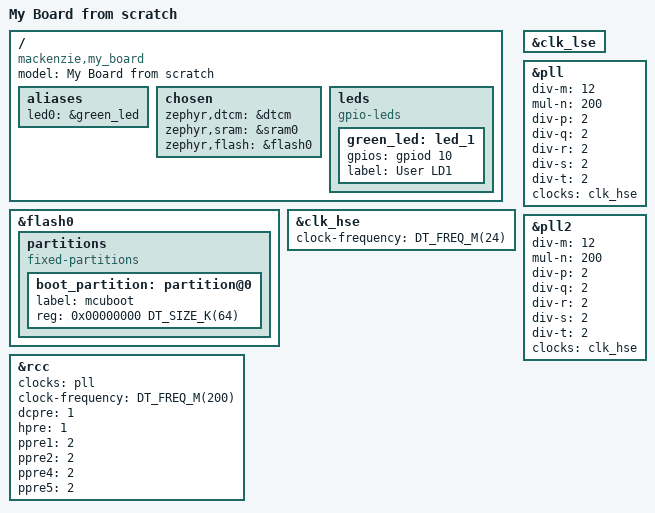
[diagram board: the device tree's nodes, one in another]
/dts-v1/;
#include <st/h7rs/stm32h7s3X8.dtsi>


/{
    model =  "My Board from scratch";
    compatible = "mackenzie,my_board";
    aliases {
		led0 = &green_led;
		// I think spi flash may be needed
	};
    chosen {
        // Lets go with no consol build
		zephyr,dtcm = &dtcm;
		zephyr,sram = &sram0;
		zephyr,flash = &flash0;
	};
    // GPIO set up done in 
    leds: leds {
		compatible = "gpio-leds";

		green_led: led_1 {
			gpios = <&gpiod 10 GPIO_ACTIVE_HIGH>;
			label = "User LD1";
		};

	};
};

&flash0 {
	partitions {
		compatible = "fixed-partitions";
		#address-cells = <1>;
		#size-cells = <1>;

		/* Set the partitions with first MB to make use of the whole Bank1 */
		boot_partition: partition@0 {
			label = "mcuboot";
			reg = <0x00000000 DT_SIZE_K(64)>;
		};
	};
};

// Clock def
&clk_hse {
	clock-frequency = <DT_FREQ_M(24)>;
	status = "okay";
};

&clk_lse {
	status = "okay";
};

&pll {
	div-m = <12>;
	mul-n = <200>;
	div-p = <2>;
	div-q = <2>;
	div-r = <2>;
	div-s = <2>;
	div-t = <2>;
	clocks = <&clk_hse>;
	status = "okay";
};

/* PLL2 for clocking the xspi peripheral */
&pll2 {
	div-m = <12>;
	mul-n = <200>;
	div-p = <2>;
	div-q = <2>;
	div-r = <2>;
	div-s = <2>;
	div-t = <2>;
	clocks = <&clk_hse>;
	status = "okay";
};

&rcc {
	clocks = <&pll>;
	clock-frequency = <DT_FREQ_M(200)>;
	dcpre = <1>;
	hpre = <1>;
	ppre1 = <2>;
	ppre2 = <2>;
	ppre4 = <2>;
	ppre5 = <2>;
};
